# iom480ae register map
Registers are 32-bit, access not given, no defined reset value unless marked. A register's access mark holds for its fields unless they carry their own. Addresses are absolute; registers are grouped by the start of their names; [hi:lo] are bit positions; {n}, {i} and the like mark numbered series.

## I2S
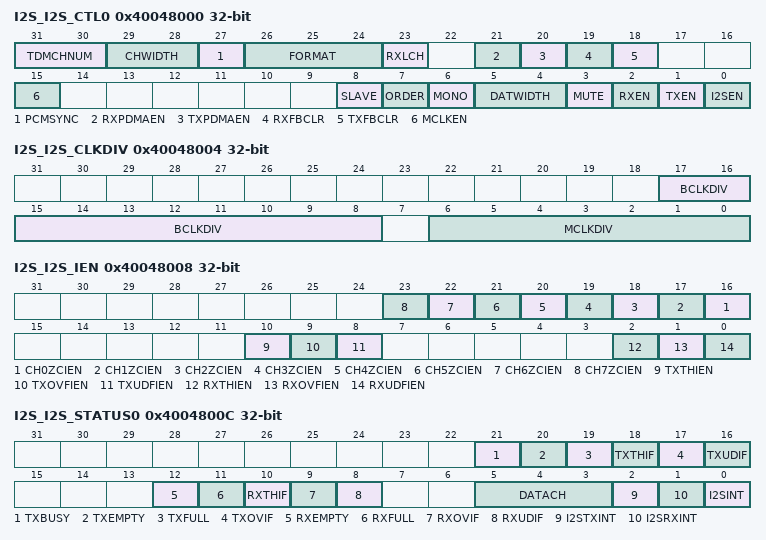
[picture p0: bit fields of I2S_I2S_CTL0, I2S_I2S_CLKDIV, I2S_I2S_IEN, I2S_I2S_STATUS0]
0x40048000 I2S_I2S_CTL0
  [31:30] TDMCHNUM, [29:28] CHWIDTH, [27] PCMSYNC, [26:24] FORMAT, [23] RXLCH, [21] RXPDMAEN, [20] TXPDMAEN, [19] RXFBCLR, [18] TXFBCLR, [15] MCLKEN, [8] SLAVE, [7] ORDER, [6] MONO, [5:4] DATWIDTH, [3] MUTE, [2] RXEN, [1] TXEN, [0] I2SEN
0x40048004 I2S_I2S_CLKDIV
  [17:8] BCLKDIV, [6:0] MCLKDIV
0x40048008 I2S_I2S_IEN
  [n+16] CH{n}ZCIEN (n=0..7), [10] TXTHIEN, [9] TXOVFIEN, [8] TXUDFIEN, [2] RXTHIEN, [1] RXOVFIEN, [0] RXUDFIEN
0x4004800C I2S_I2S_STATUS0
  [21] TXBUSY, [20] TXEMPTY, [19] TXFULL, [18] TXTHIF, [17] TXOVIF, [16] TXUDIF, [12] RXEMPTY, [11] RXFULL, [10] RXTHIF, [9] RXOVIF, [8] RXUDIF, [5:3] DATACH, [2] I2STXINT, [1] I2SRXINT, [0] I2SINT
0x40048010 I2S_I2S_TXFIFO
0x40048014 I2S_I2S_RXFIFO
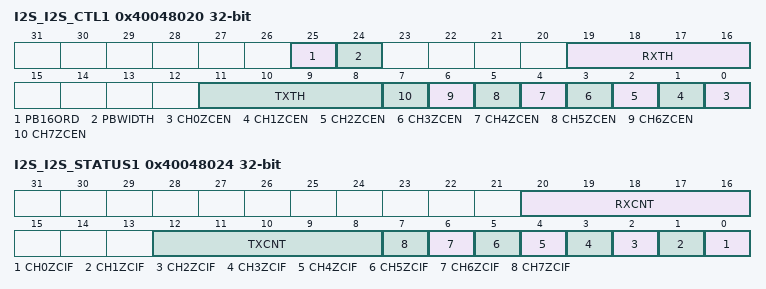
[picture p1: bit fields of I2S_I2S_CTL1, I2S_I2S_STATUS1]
0x40048020 I2S_I2S_CTL1
  [25] PB16ORD, [24] PBWIDTH, [19:16] RXTH, [11:8] TXTH, [n] CH{n}ZCEN (n=0..7)
0x40048024 I2S_I2S_STATUS1
  [20:16] RXCNT, [12:8] TXCNT, [n] CH{n}ZCIF (n=0..7)

## SPI0
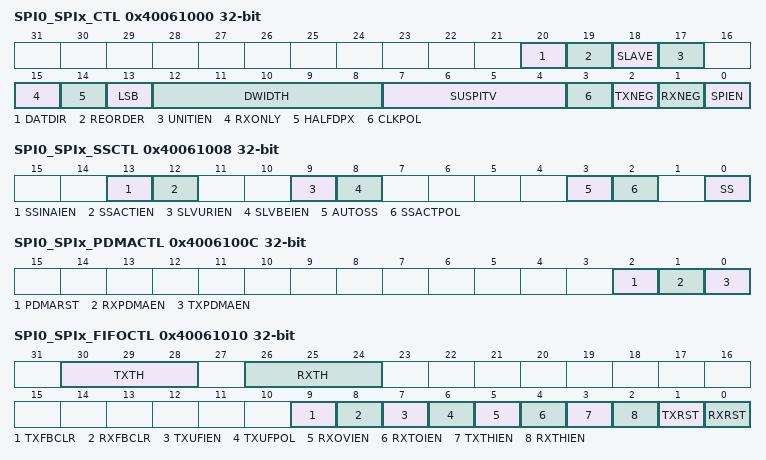
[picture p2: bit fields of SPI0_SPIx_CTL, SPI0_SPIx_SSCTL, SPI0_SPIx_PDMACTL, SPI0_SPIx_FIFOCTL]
0x40061000 SPI0_SPIx_CTL
  [20] DATDIR, [19] REORDER, [18] SLAVE, [17] UNITIEN, [15] RXONLY, [14] HALFDPX, [13] LSB, [12:8] DWIDTH, [7:4] SUSPITV, [3] CLKPOL, [2] TXNEG, [1] RXNEG, [0] SPIEN
0x40061004 SPI0_SPIx_CLKDIV
  [8:0] DIVIDER
0x40061008 SPI0_SPIx_SSCTL
  [13] SSINAIEN, [12] SSACTIEN, [9] SLVURIEN, [8] SLVBEIEN, [3] AUTOSS, [2] SSACTPOL, [0] SS
0x4006100C SPI0_SPIx_PDMACTL
  [2] PDMARST, [1] RXPDMAEN, [0] TXPDMAEN
0x40061010 SPI0_SPIx_FIFOCTL
  [30:28] TXTH, [26:24] RXTH, [9] TXFBCLR, [8] RXFBCLR, [7] TXUFIEN, [6] TXUFPOL, [5] RXOVIEN, [4] RXTOIEN, [3] TXTHIEN, [2] RXTHIEN, [1] TXRST, [0] RXRST
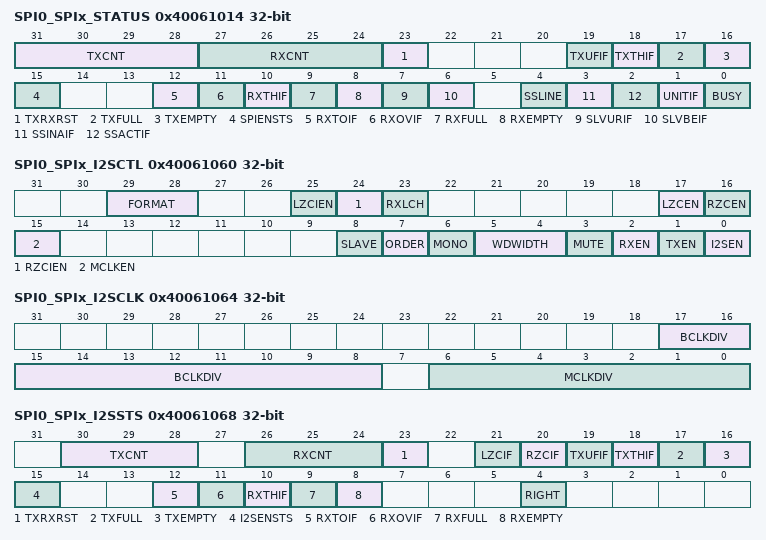
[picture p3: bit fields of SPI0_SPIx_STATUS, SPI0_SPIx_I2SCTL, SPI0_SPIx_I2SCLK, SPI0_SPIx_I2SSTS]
0x40061014 SPI0_SPIx_STATUS
  [31:28] TXCNT, [27:24] RXCNT, [23] TXRXRST, [19] TXUFIF, [18] TXTHIF, [17] TXFULL, [16] TXEMPTY, [15] SPIENSTS, [12] RXTOIF, [11] RXOVIF, [10] RXTHIF, [9] RXFULL, [8] RXEMPTY, [7] SLVURIF, [6] SLVBEIF, [4] SSLINE, [3] SSINAIF, [2] SSACTIF, [1] UNITIF, [0] BUSY
0x40061020 SPI0_SPIx_TX
0x40061030 SPI0_SPIx_RX
0x40061060 SPI0_SPIx_I2SCTL
  [29:28] FORMAT, [25] LZCIEN, [24] RZCIEN, [23] RXLCH, [17] LZCEN, [16] RZCEN, [15] MCLKEN, [8] SLAVE, [7] ORDER, [6] MONO, [5:4] WDWIDTH, [3] MUTE, [2] RXEN, [1] TXEN, [0] I2SEN
0x40061064 SPI0_SPIx_I2SCLK
  [17:8] BCLKDIV, [6:0] MCLKDIV
0x40061068 SPI0_SPIx_I2SSTS
  [30:28] TXCNT, [26:24] RXCNT, [23] TXRXRST, [21] LZCIF, [20] RZCIF, [19] TXUFIF, [18] TXTHIF, [17] TXFULL, [16] TXEMPTY, [15] I2SENSTS, [12] RXTOIF, [11] RXOVIF, [10] RXTHIF, [9] RXFULL, [8] RXEMPTY, [4] RIGHT

## SPI1
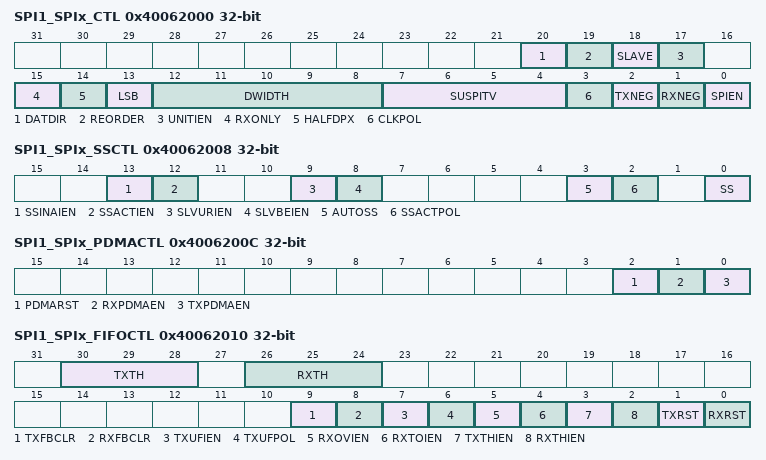
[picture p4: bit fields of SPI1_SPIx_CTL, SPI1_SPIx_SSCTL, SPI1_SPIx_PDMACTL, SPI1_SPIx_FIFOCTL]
0x40062000 SPI1_SPIx_CTL
  [20] DATDIR, [19] REORDER, [18] SLAVE, [17] UNITIEN, [15] RXONLY, [14] HALFDPX, [13] LSB, [12:8] DWIDTH, [7:4] SUSPITV, [3] CLKPOL, [2] TXNEG, [1] RXNEG, [0] SPIEN
0x40062004 SPI1_SPIx_CLKDIV
  [8:0] DIVIDER
0x40062008 SPI1_SPIx_SSCTL
  [13] SSINAIEN, [12] SSACTIEN, [9] SLVURIEN, [8] SLVBEIEN, [3] AUTOSS, [2] SSACTPOL, [0] SS
0x4006200C SPI1_SPIx_PDMACTL
  [2] PDMARST, [1] RXPDMAEN, [0] TXPDMAEN
0x40062010 SPI1_SPIx_FIFOCTL
  [30:28] TXTH, [26:24] RXTH, [9] TXFBCLR, [8] RXFBCLR, [7] TXUFIEN, [6] TXUFPOL, [5] RXOVIEN, [4] RXTOIEN, [3] TXTHIEN, [2] RXTHIEN, [1] TXRST, [0] RXRST
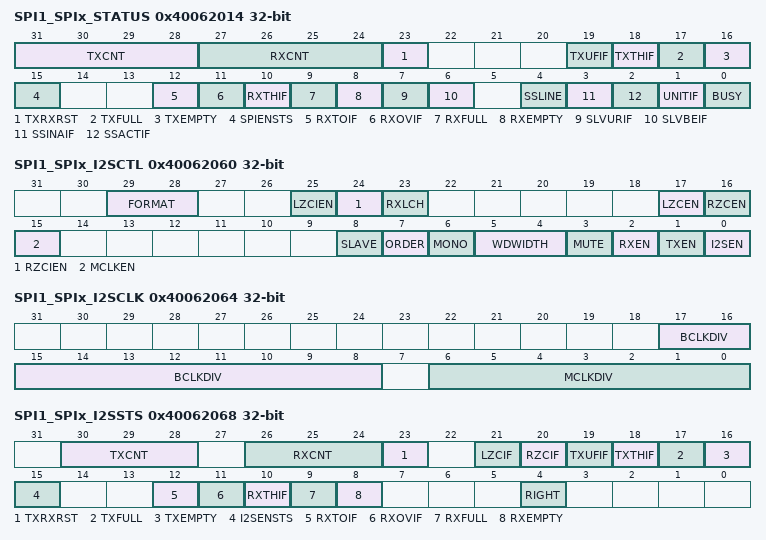
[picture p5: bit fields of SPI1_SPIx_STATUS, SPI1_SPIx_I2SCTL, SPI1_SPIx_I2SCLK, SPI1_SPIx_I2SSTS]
0x40062014 SPI1_SPIx_STATUS
  [31:28] TXCNT, [27:24] RXCNT, [23] TXRXRST, [19] TXUFIF, [18] TXTHIF, [17] TXFULL, [16] TXEMPTY, [15] SPIENSTS, [12] RXTOIF, [11] RXOVIF, [10] RXTHIF, [9] RXFULL, [8] RXEMPTY, [7] SLVURIF, [6] SLVBEIF, [4] SSLINE, [3] SSINAIF, [2] SSACTIF, [1] UNITIF, [0] BUSY
0x40062020 SPI1_SPIx_TX
0x40062030 SPI1_SPIx_RX
0x40062060 SPI1_SPIx_I2SCTL
  [29:28] FORMAT, [25] LZCIEN, [24] RZCIEN, [23] RXLCH, [17] LZCEN, [16] RZCEN, [15] MCLKEN, [8] SLAVE, [7] ORDER, [6] MONO, [5:4] WDWIDTH, [3] MUTE, [2] RXEN, [1] TXEN, [0] I2SEN
0x40062064 SPI1_SPIx_I2SCLK
  [17:8] BCLKDIV, [6:0] MCLKDIV
0x40062068 SPI1_SPIx_I2SSTS
  [30:28] TXCNT, [26:24] RXCNT, [23] TXRXRST, [21] LZCIF, [20] RZCIF, [19] TXUFIF, [18] TXTHIF, [17] TXFULL, [16] TXEMPTY, [15] I2SENSTS, [12] RXTOIF, [11] RXOVIF, [10] RXTHIF, [9] RXFULL, [8] RXEMPTY, [4] RIGHT
